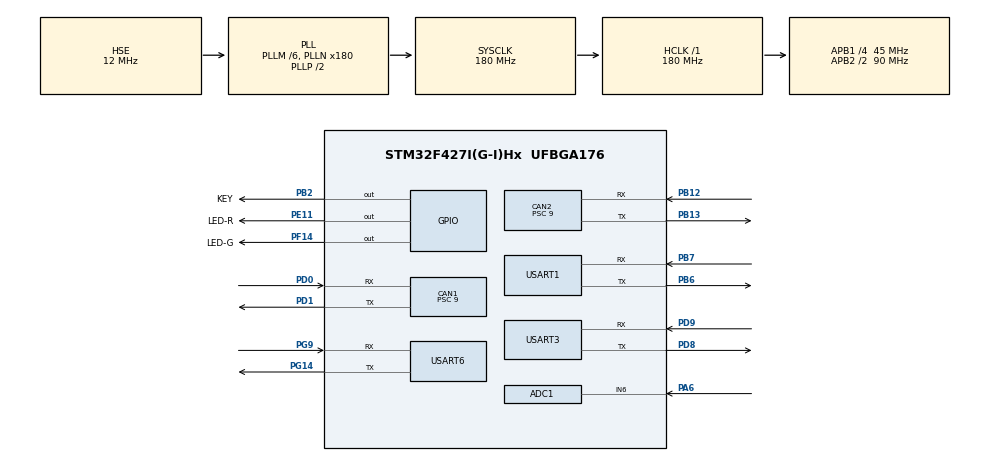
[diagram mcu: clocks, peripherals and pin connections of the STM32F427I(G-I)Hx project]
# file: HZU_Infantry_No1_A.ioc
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ADC1.Channel-0\#ChannelRegularConversion=ADC_CHANNEL_6
ADC1.NbrOfConversionFlag=1
ADC1.Rank-0\#ChannelRegularConversion=1
ADC1.SamplingTime-0\#ChannelRegularConversion=ADC_SAMPLETIME_3CYCLES
ADC1.master=1
CAN1.BS1=CAN_BS1_3TQ
CAN1.BS2=CAN_BS2_1TQ
CAN1.CalculateBaudRate=1000000
CAN1.CalculateTimeBit=1000
CAN1.CalculateTimeQuantum=200.0
CAN1.Prescaler=9
CAN2.BS1=CAN_BS1_3TQ
CAN2.BS2=CAN_BS2_1TQ
CAN2.CalculateBaudRate=1000000
CAN2.CalculateTimeBit=1000
CAN2.CalculateTimeQuantum=200.0
CAN2.Prescaler=9
Dma.Request0=USART3_RX
Dma.Request1=USART3_TX
Dma.USART3_RX.0.Direction=DMA_PERIPH_TO_MEMORY
Dma.USART3_RX.0.FIFOMode=DMA_FIFOMODE_DISABLE
Dma.USART3_RX.0.Instance=DMA1_Stream1
Dma.USART3_RX.0.MemDataAlignment=DMA_MDATAALIGN_BYTE
Dma.USART3_RX.0.MemInc=DMA_MINC_ENABLE
Dma.USART3_RX.0.Mode=DMA_CIRCULAR
Dma.USART3_RX.0.PeriphDataAlignment=DMA_PDATAALIGN_BYTE
Dma.USART3_RX.0.PeriphInc=DMA_PINC_DISABLE
Dma.USART3_RX.0.Priority=DMA_PRIORITY_VERY_HIGH
Dma.USART3_TX.1.Direction=DMA_MEMORY_TO_PERIPH
Dma.USART3_TX.1.FIFOMode=DMA_FIFOMODE_DISABLE
Dma.USART3_TX.1.Instance=DMA1_Stream3
Dma.USART3_TX.1.MemDataAlignment=DMA_MDATAALIGN_BYTE
Dma.USART3_TX.1.MemInc=DMA_MINC_ENABLE
Dma.USART3_TX.1.Mode=DMA_CIRCULAR
Dma.USART3_TX.1.PeriphDataAlignment=DMA_PDATAALIGN_BYTE
Dma.USART3_TX.1.PeriphInc=DMA_PINC_DISABLE
Dma.USART3_TX.1.Priority=DMA_PRIORITY_VERY_HIGH
FREERTOS.INCLUDE_pcTaskGetTaskName=1
FREERTOS.INCLUDE_uxTaskGetStackHighWaterMark2=1
FREERTOS.INCLUDE_vTaskCleanUpResources=1
FREERTOS.INCLUDE_xEventGroupSetBitFromISR=1
FREERTOS.INCLUDE_xSemaphoreGetMutexHolder=1
FREERTOS.INCLUDE_xTaskAbortDelay=1
FREERTOS.INCLUDE_xTaskGetCurrentTaskHandle=1
FREERTOS.INCLUDE_xTaskGetHandle=1
FREERTOS.Tasks01=defaultTask,24,256,StartDefaultTask,Default,NULL,Dynamic,NULL,NULL
FREERTOS.configENABLE_BACKWARD_COMPATIBILITY=0
FREERTOS.configENABLE_FPU=1
FREERTOS.configGENERATE_RUN_TIME_STATS=1
FREERTOS.configRECORD_STACK_HIGH_ADDRESS=1
FREERTOS.configUSE_STATS_FORMATTING_FUNCTIONS=1
Mcu.Family=STM32F4
Mcu.Name=STM32F427I(G-I)Hx
Mcu.Package=UFBGA176
NVIC.ADC_IRQn=true\:5\:0\:false\:false\:true\:true\:true\:true\:true
NVIC.CAN1_RX0_IRQn=true\:5\:0\:false\:false\:true\:true\:true\:true\:true
NVIC.CAN1_RX1_IRQn=true\:5\:0\:false\:false\:true\:true\:true\:true\:true
NVIC.CAN1_TX_IRQn=true\:5\:0\:false\:false\:true\:true\:true\:true\:true
NVIC.CAN2_RX0_IRQn=true\:5\:0\:false\:false\:true\:true\:true\:true\:true
NVIC.CAN2_RX1_IRQn=true\:5\:0\:false\:false\:true\:true\:true\:true\:true
NVIC.CAN2_TX_IRQn=true\:5\:0\:false\:false\:true\:true\:true\:true\:true
NVIC.DMA1_Stream1_IRQn=true\:5\:0\:false\:false\:true\:true\:false\:true\:true
NVIC.DMA1_Stream3_IRQn=true\:5\:0\:false\:false\:true\:true\:false\:true\:true
NVIC.PriorityGroup=NVIC_PRIORITYGROUP_4
NVIC.TIM1_UP_TIM10_IRQn=true\:0\:0\:false\:false\:true\:false\:false\:true\:true
NVIC.TIM3_IRQn=true\:5\:0\:false\:false\:true\:true\:true\:true\:true
NVIC.TIM7_IRQn=true\:5\:0\:false\:false\:true\:true\:true\:true\:true
NVIC.TimeBase=TIM1_UP_TIM10_IRQn
NVIC.TimeBaseIP=TIM1
NVIC.USART1_IRQn=true\:5\:0\:false\:false\:true\:true\:true\:true\:true
NVIC.USART3_IRQn=true\:5\:0\:false\:false\:true\:true\:true\:true\:true
NVIC.USART6_IRQn=true\:5\:0\:false\:false\:true\:true\:true\:true\:true
PA13.Mode=Serial_Wire
PA13.Signal=SYS_JTMS-SWDIO
PA14.Mode=Serial_Wire
PA14.Signal=SYS_JTCK-SWCLK
PA6.Signal=ADCx_IN6
PB12.Mode=CAN_Activate
PB12.Signal=CAN2_RX
PB13.Mode=CAN_Activate
PB13.Signal=CAN2_TX
PB2/BOOT1.GPIO_Label=KEY
PB2/BOOT1.GPIO_ModeDefaultOutputPP=GPIO_MODE_OUTPUT_PP
PB2/BOOT1.GPIO_PuPd=GPIO_PULLUP
PB2/BOOT1.GPIO_Speed=GPIO_SPEED_FREQ_VERY_HIGH
PB2/BOOT1.Signal=GPIO_Output
PB6.Mode=Asynchronous
PB6.Signal=USART1_TX
PB7.Mode=Asynchronous
PB7.Signal=USART1_RX
PD0.Mode=CAN_Activate
PD0.Signal=CAN1_RX
PD1.Mode=CAN_Activate
PD1.Signal=CAN1_TX
PD8.Mode=Asynchronous
PD8.Signal=USART3_TX
PD9.Mode=Asynchronous
PD9.Signal=USART3_RX
PE11.GPIO_Label=LED-R
PE11.GPIO_PuPd=GPIO_PULLUP
PE11.GPIO_Speed=GPIO_SPEED_FREQ_VERY_HIGH
PE11.Signal=GPIO_Output
PF14.GPIO_Label=LED-G
PF14.GPIO_PuPd=GPIO_PULLUP
PF14.GPIO_Speed=GPIO_SPEED_FREQ_VERY_HIGH
PF14.Signal=GPIO_Output
PG14.Mode=Asynchronous
PG14.Signal=USART6_TX
PG9.Mode=Asynchronous
PG9.Signal=USART6_RX
PH0/OSC_IN.Mode=HSE-External-Oscillator
PH0/OSC_IN.Signal=RCC_OSC_IN
PH1/OSC_OUT.Mode=HSE-External-Oscillator
PH1/OSC_OUT.Signal=RCC_OSC_OUT
ProjectManager.HeapSize=0x200
ProjectManager.StackSize=0x400
ProjectManager.TargetToolchain=MDK-ARM V5.27
RCC.48MHZClocksFreq_Value=90000000
RCC.AHBFreq_Value=180000000
RCC.APB1CLKDivider=RCC_HCLK_DIV4
RCC.APB1Freq_Value=45000000
RCC.APB1TimFreq_Value=90000000
RCC.APB2CLKDivider=RCC_HCLK_DIV2
RCC.APB2Freq_Value=90000000
RCC.APB2TimFreq_Value=180000000
RCC.CortexFreq_Value=180000000
RCC.HCLKFreq_Value=180000000
RCC.HSE_VALUE=12000000
RCC.HSI_VALUE=16000000
RCC.LSE_VALUE=32768
RCC.PLLM=6
RCC.PLLN=180
RCC.PLLSourceVirtual=RCC_PLLSOURCE_HSE
RCC.SYSCLKFreq_VALUE=180000000
RCC.SYSCLKSource=RCC_SYSCLKSOURCE_PLLCLK
RCC.VCOOutputFreq_Value=360000000
SH.ADCx_IN6.0=ADC1_IN6,IN6
TIM3.Period=54
TIM3.Prescaler=84
TIM7.AutoReloadPreload=TIM_AUTORELOAD_PRELOAD_ENABLE
TIM7.Period=999
TIM7.Prescaler=89
USART1.VirtualMode=VM_ASYNC
USART3.VirtualMode=VM_ASYNC
USART6.VirtualMode=VM_ASYNC
VP_FREERTOS_VS_CMSIS_V2.Mode=CMSIS_V2
VP_SYS_VS_tim1.Mode=TIM1
VP_TIM3_VS_ClockSourceINT.Mode=Internal
VP_TIM7_VS_ClockSourceINT.Mode=Enable_Timer
board=custom

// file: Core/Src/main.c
/* USER CODE BEGIN Header */
/**
  ******************************************************************************
  * @file           : main.c
  * @brief          : Main program body
  ******************************************************************************
  * @attention
  *
  * <h2><center>&copy; Copyright (c) 2021 STMicroelectronics.
  * All rights reserved.</center></h2>
  *
  * This software component is licensed by ST under BSD 3-Clause license,
  * the "License"; You may not use this file except in compliance with the
  * License. You may obtain a copy of the License at:
  *                        opensource.org/licenses/BSD-3-Clause
  *
  ******************************************************************************
  */
/* USER CODE END Header */
#include "main.h"
#include "cmsis_os.h"
#include "adc.h"
#include "can.h"
#include "dma.h"
#include "tim.h"
#include "usart.h"
#include "gpio.h"

/* USER CODE BEGIN Includes */
#include "string.h"
#include "chassis_task.h"
/* USER CODE END Includes */

void SystemClock_Config(void);
void MX_FREERTOS_Init(void);
/* USER CODE BEGIN PFP */
extern volatile uint64_t freertos_run_time;
/* USER CODE END PFP */

int main(void)
{

  /* MCU Configuration--------------------------------------------------------*/

  /* Reset of all peripherals, Initializes the Flash interface and the Systick. */
   HAL_Init();

  /* Configure the system clock */
  SystemClock_Config();

  /* Initialize all configured peripherals */
  MX_GPIO_Init();
  MX_DMA_Init();
  MX_CAN1_Init();
  MX_CAN2_Init();
  MX_TIM7_Init();
  MX_USART3_UART_Init();
  MX_ADC1_Init();
  MX_USART1_UART_Init();
  MX_USART6_UART_Init();
  MX_TIM3_Init();
  /* USER CODE BEGIN 2 */
  freertos_run_tim3_configuration();
  CAN_APP_INIT();    //can过滤器初始化
  LED_Init();        // OLED屏幕初始化
  delay_init(180);  // 这个delay_init必须放在OLED初始化后面

  // check_connect(&connect_data);//判断底盘云台是否连接
  /* USER CODE END 2 */

  /* Init scheduler */
  osKernelInitialize();  /* Call init function for freertos objects (in freertos.c) */
  MX_FREERTOS_Init();
  /* Start scheduler */
  osKernelStart();

  /* We should never get here as control is now taken by the scheduler */
  /* Infinite loop */
  while (1)
  {

  }
}

void SystemClock_Config(void)
{
  RCC_OscInitTypeDef RCC_OscInitStruct = {0};
  RCC_ClkInitTypeDef RCC_ClkInitStruct = {0};

  /** Configure the main internal regulator output voltage
  */
  __HAL_RCC_PWR_CLK_ENABLE();
  __HAL_PWR_VOLTAGESCALING_CONFIG(PWR_REGULATOR_VOLTAGE_SCALE1);
  /** Initializes the RCC Oscillators according to the specified parameters
  * in the RCC_OscInitTypeDef structure.
  */
  RCC_OscInitStruct.OscillatorType = RCC_OSCILLATORTYPE_HSE;
  RCC_OscInitStruct.HSEState = RCC_HSE_ON;
  RCC_OscInitStruct.PLL.PLLState = RCC_PLL_ON;
  RCC_OscInitStruct.PLL.PLLSource = RCC_PLLSOURCE_HSE;
  RCC_OscInitStruct.PLL.PLLM = 6;
  RCC_OscInitStruct.PLL.PLLN = 180;
  RCC_OscInitStruct.PLL.PLLP = RCC_PLLP_DIV2;
  RCC_OscInitStruct.PLL.PLLQ = 4;
  if (HAL_RCC_OscConfig(&RCC_OscInitStruct) != HAL_OK)
  {
    Error_Handler();
  }
  /** Activate the Over-Drive mode
  */
  if (HAL_PWREx_EnableOverDrive() != HAL_OK)
  {
    Error_Handler();
  }
  /** Initializes the CPU, AHB and APB buses clocks
  */
  RCC_ClkInitStruct.ClockType = RCC_CLOCKTYPE_HCLK|RCC_CLOCKTYPE_SYSCLK
                              |RCC_CLOCKTYPE_PCLK1|RCC_CLOCKTYPE_PCLK2;
  RCC_ClkInitStruct.SYSCLKSource = RCC_SYSCLKSOURCE_PLLCLK;
  RCC_ClkInitStruct.AHBCLKDivider = RCC_SYSCLK_DIV1;
  RCC_ClkInitStruct.APB1CLKDivider = RCC_HCLK_DIV4;
  RCC_ClkInitStruct.APB2CLKDivider = RCC_HCLK_DIV2;

  if (HAL_RCC_ClockConfig(&RCC_ClkInitStruct, FLASH_LATENCY_5) != HAL_OK)
  {
    Error_Handler();
  }
}

/* USER CODE BEGIN 4 */
extern chassis_control_data_t chassis_control_data;
extern chassis_pid_t chassis_pid;
/* USER CODE END 4 */

 /**
  * @brief  Period elapsed callback in non blocking mode
  * @note   This function is called  when TIM1 interrupt took place, inside
  * HAL_TIM_IRQHandler(). It makes a direct call to HAL_IncTick() to increment
  * a global variable "uwTick" used as application time base.
  * @param  htim : TIM handle
  * @retval None
  */
void HAL_TIM_PeriodElapsedCallback(TIM_HandleTypeDef *htim)
{
  if (htim->Instance == TIM1) {
    HAL_IncTick();
  }
  /* USER CODE BEGIN Callback 1 */
else if(htim->Instance == TIM3)
	{
		freertos_run_time ++;
	}
else if(htim->Instance== htim7.Instance)//中断执行保证速度稳定
    {
        // if(tim7_cnt++==1000)
        // {
        //     tim7_cnt=0;
        //     LED_PrintValueI(10,5,time_s++);
        // }
        chassis_set_and_fdb_update(&chassis_control_data, &chassis_pid);
		    // chassis_pid_calculate(&chassis_control_data, &chassis_pid);

    }
  /* USER CODE END Callback 1 */
}

void Error_Handler(void)
{
  __disable_irq();
  while (1)
  {
  }
}

/************************ (C) COPYRIGHT STMicroelectronics *****END OF FILE****/
